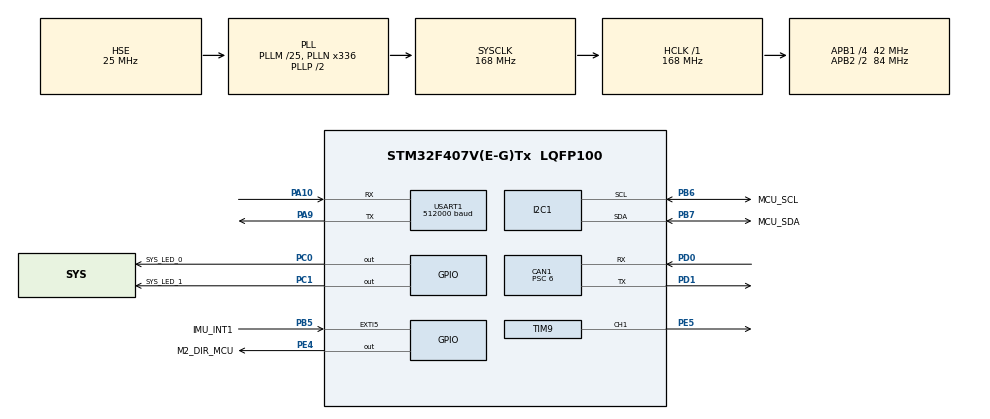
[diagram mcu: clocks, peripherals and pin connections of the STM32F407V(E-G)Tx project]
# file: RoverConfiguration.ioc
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CAN1.BS1=CAN_BS1_8TQ
CAN1.BS2=CAN_BS2_5TQ
CAN1.CalculateBaudRate=500000
CAN1.CalculateTimeBit=2000
CAN1.CalculateTimeQuantum=142.85714285714286
CAN1.Prescaler=6
CAN1.RFLM=ENABLE
CAN1.SJW=CAN_SJW_2TQ
CAN1.TXFP=ENABLE
Dma.Request0=USART1_RX
Dma.Request1=USART1_TX
Dma.USART1_RX.0.Direction=DMA_PERIPH_TO_MEMORY
Dma.USART1_RX.0.FIFOMode=DMA_FIFOMODE_DISABLE
Dma.USART1_RX.0.Instance=DMA2_Stream2
Dma.USART1_RX.0.MemDataAlignment=DMA_MDATAALIGN_BYTE
Dma.USART1_RX.0.MemInc=DMA_MINC_ENABLE
Dma.USART1_RX.0.Mode=DMA_NORMAL
Dma.USART1_RX.0.PeriphDataAlignment=DMA_PDATAALIGN_BYTE
Dma.USART1_RX.0.PeriphInc=DMA_PINC_DISABLE
Dma.USART1_RX.0.Priority=DMA_PRIORITY_HIGH
Dma.USART1_TX.1.Direction=DMA_MEMORY_TO_PERIPH
Dma.USART1_TX.1.FIFOMode=DMA_FIFOMODE_DISABLE
Dma.USART1_TX.1.Instance=DMA2_Stream7
Dma.USART1_TX.1.MemDataAlignment=DMA_MDATAALIGN_BYTE
Dma.USART1_TX.1.MemInc=DMA_MINC_ENABLE
Dma.USART1_TX.1.Mode=DMA_NORMAL
Dma.USART1_TX.1.PeriphDataAlignment=DMA_PDATAALIGN_BYTE
Dma.USART1_TX.1.PeriphInc=DMA_PINC_DISABLE
Dma.USART1_TX.1.Priority=DMA_PRIORITY_HIGH
FREERTOS.BinarySemaphores01=IMUBinarySem,Dynamic,NULL,Available
FREERTOS.MEMORY_ALLOCATION=2
FREERTOS.Tasks01=defaultTask,1,128,StartSysTask,As weak,NULL,Dynamic,NULL,NULL;myTask02,-3,512,StartPublisher2Task,As weak,NULL,Dynamic,NULL,NULL;myTask04,-3,128,StartServoTask,As weak,NULL,Dynamic,NULL,NULL;myTask05,-3,128,StartSysLEDTask,As weak,NULL,Dynamic,NULL,NULL;myTask06,-3,512,StartDriverTask,As weak,NULL,Dynamic,NULL,NULL;myTask07,-3,1024,StartIMUTask,As weak,NULL,Dynamic,NULL,NULL
FREERTOS.configMINIMAL_STACK_SIZE=128
Mcu.Family=STM32F4
Mcu.Name=STM32F407V(E-G)Tx
Mcu.Package=LQFP100
NVIC.CAN1_RX0_IRQn=true\:6\:0\:true\:false\:true\:true\:true\:true\:true
NVIC.CAN1_RX1_IRQn=true\:6\:0\:true\:false\:true\:true\:true\:true\:true
NVIC.CAN1_SCE_IRQn=true\:6\:0\:true\:false\:true\:true\:true\:true\:true
NVIC.CAN1_TX_IRQn=true\:6\:0\:true\:false\:true\:true\:true\:true\:true
NVIC.DMA2_Stream2_IRQn=true\:5\:0\:false\:false\:true\:true\:false\:true\:true
NVIC.DMA2_Stream7_IRQn=true\:5\:0\:false\:false\:true\:true\:false\:true\:true
NVIC.EXTI9_5_IRQn=true\:6\:0\:true\:false\:true\:true\:true\:true\:true
NVIC.PriorityGroup=NVIC_PRIORITYGROUP_4
NVIC.TIM1_UP_TIM10_IRQn=true\:15\:0\:false\:false\:true\:false\:false\:true\:true
NVIC.TIM8_TRG_COM_TIM14_IRQn=true\:5\:0\:false\:false\:true\:true\:true\:true\:true
NVIC.TimeBase=TIM1_UP_TIM10_IRQn
NVIC.TimeBaseIP=TIM1
NVIC.USART1_IRQn=true\:5\:0\:false\:false\:true\:true\:true\:true\:true
PA10.Mode=Asynchronous
PA10.Signal=USART1_RX
PA13.Mode=Serial_Wire
PA13.Signal=SYS_JTMS-SWDIO
PA14.Mode=Serial_Wire
PA14.Signal=SYS_JTCK-SWCLK
PA9.Mode=Asynchronous
PA9.Signal=USART1_TX
PB5.GPIO_Label=IMU_INT1
PB5.Signal=GPXTI5
PB6.GPIO_Label=MCU_SCL
PB6.Mode=I2C
PB6.Signal=I2C1_SCL
PB7.GPIO_Label=MCU_SDA
PB7.Mode=I2C
PB7.Signal=I2C1_SDA
PC0.GPIO_Label=SYS_LED_0
PC0.Signal=GPIO_Output
PC1.GPIO_Label=SYS_LED_1
PC1.Signal=GPIO_Output
PD0.Mode=CAN_Activate
PD0.Signal=CAN1_RX
PD1.Mode=CAN_Activate
PD1.Signal=CAN1_TX
PE4.GPIO_Label=M2_DIR_MCU
PE4.Signal=GPIO_Output
PE5.Signal=S_TIM9_CH1
PH0-OSC_IN.Mode=HSE-External-Oscillator
PH0-OSC_IN.Signal=RCC_OSC_IN
PH1-OSC_OUT.Mode=HSE-External-Oscillator
PH1-OSC_OUT.Signal=RCC_OSC_OUT
ProjectManager.HeapSize=0x3000
ProjectManager.StackSize=0x2000
ProjectManager.TargetToolchain=CMake
RCC.48MHZClocksFreq_Value=84000000
RCC.AHBFreq_Value=168000000
RCC.APB1CLKDivider=RCC_HCLK_DIV4
RCC.APB1Freq_Value=42000000
RCC.APB1TimFreq_Value=84000000
RCC.APB2CLKDivider=RCC_HCLK_DIV2
RCC.APB2Freq_Value=84000000
RCC.APB2TimFreq_Value=168000000
RCC.CortexFreq_Value=168000000
RCC.HCLKFreq_Value=168000000
RCC.HSE_VALUE=25000000
RCC.HSI_VALUE=16000000
RCC.LSE_VALUE=32768
RCC.PLLM=25
RCC.PLLN=336
RCC.PLLSourceVirtual=RCC_PLLSOURCE_HSE
RCC.SYSCLKFreq_VALUE=168000000
RCC.SYSCLKSource=RCC_SYSCLKSOURCE_PLLCLK
RCC.VCOOutputFreq_Value=336000000
SH.S_TIM9_CH1.0=TIM9_CH1,PWM Generation1 CH1
TIM14.AutoReloadPreload=TIM_AUTORELOAD_PRELOAD_DISABLE
TIM14.Period=1000
TIM14.Prescaler=83
TIM9.AutoReloadPreload=TIM_AUTORELOAD_PRELOAD_ENABLE
TIM9.Channel-PWM\ Generation1\ CH1=TIM_CHANNEL_1
TIM9.OCPolarity_1=TIM_OCPOLARITY_HIGH
TIM9.Period=1000-1
TIM9.Prescaler=168-1
TIM9.Pulse-PWM\ Generation1\ CH1=500
USART1.BaudRate=512000
USART1.VirtualMode=VM_ASYNC
VP_FREERTOS_VS_CMSIS_V1.Mode=CMSIS_V1
VP_SYS_VS_tim1.Mode=TIM1
VP_TIM14_VS_ClockSourceINT.Mode=Enable_Timer
board=custom

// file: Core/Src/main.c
/* USER CODE BEGIN Header */
/**
  ******************************************************************************
  * @file           : main.c
  * @brief          : Main program body
  ******************************************************************************
  * @attention
  *
  * Copyright (c) 2024 STMicroelectronics.
  * All rights reserved.
  *
  * This software is licensed under terms that can be found in the LICENSE file
  * in the root directory of this software component.
  * If no LICENSE file comes with this software, it is provided AS-IS.
  *
  ******************************************************************************
  */
/* USER CODE END Header */
#include "main.h"
#include "cmsis_os.h"
#include "can.h"
#include "dma.h"
#include "i2c.h"
#include "tim.h"
#include "usart.h"
#include "gpio.h"

/* USER CODE BEGIN Includes */
#include "maincpp.h"
/* USER CODE END Includes */

void SystemClock_Config(void);
void MX_FREERTOS_Init(void);

int main(void)
{

  /* MCU Configuration--------------------------------------------------------*/

  /* Reset of all peripherals, Initializes the Flash interface and the Systick. */
  HAL_Init();

  /* Configure the system clock */
  SystemClock_Config();

  /* Initialize all configured peripherals */
  MX_GPIO_Init();
  MX_DMA_Init();
  MX_CAN1_Init();
  MX_TIM14_Init();
  MX_USART1_UART_Init();
  MX_TIM9_Init();
  MX_I2C1_Init();

  /* Call init function for freertos objects (in cmsis_os2.c) */
  MX_FREERTOS_Init();

  /* Start scheduler */
  osKernelStart();

  /* We should never get here as control is now taken by the scheduler */

  /* Infinite loop */
  while (1)
  {

  }
}

void SystemClock_Config(void)
{
  RCC_OscInitTypeDef RCC_OscInitStruct = {0};
  RCC_ClkInitTypeDef RCC_ClkInitStruct = {0};

  /** Configure the main internal regulator output voltage
  */
  __HAL_RCC_PWR_CLK_ENABLE();
  __HAL_PWR_VOLTAGESCALING_CONFIG(PWR_REGULATOR_VOLTAGE_SCALE1);

  /** Initializes the RCC Oscillators according to the specified parameters
  * in the RCC_OscInitTypeDef structure.
  */
  RCC_OscInitStruct.OscillatorType = RCC_OSCILLATORTYPE_HSE;
  RCC_OscInitStruct.HSEState = RCC_HSE_ON;
  RCC_OscInitStruct.PLL.PLLState = RCC_PLL_ON;
  RCC_OscInitStruct.PLL.PLLSource = RCC_PLLSOURCE_HSE;
  RCC_OscInitStruct.PLL.PLLM = 25;
  RCC_OscInitStruct.PLL.PLLN = 336;
  RCC_OscInitStruct.PLL.PLLP = RCC_PLLP_DIV2;
  RCC_OscInitStruct.PLL.PLLQ = 4;
  if (HAL_RCC_OscConfig(&RCC_OscInitStruct) != HAL_OK)
  {
    Error_Handler();
  }

  /** Initializes the CPU, AHB and APB buses clocks
  */
  RCC_ClkInitStruct.ClockType = RCC_CLOCKTYPE_HCLK|RCC_CLOCKTYPE_SYSCLK
                              |RCC_CLOCKTYPE_PCLK1|RCC_CLOCKTYPE_PCLK2;
  RCC_ClkInitStruct.SYSCLKSource = RCC_SYSCLKSOURCE_PLLCLK;
  RCC_ClkInitStruct.AHBCLKDivider = RCC_SYSCLK_DIV1;
  RCC_ClkInitStruct.APB1CLKDivider = RCC_HCLK_DIV4;
  RCC_ClkInitStruct.APB2CLKDivider = RCC_HCLK_DIV2;

  if (HAL_RCC_ClockConfig(&RCC_ClkInitStruct, FLASH_LATENCY_5) != HAL_OK)
  {
    Error_Handler();
  }
}

void HAL_TIM_PeriodElapsedCallback(TIM_HandleTypeDef *htim)
{
  if (htim->Instance == TIM1) {
    HAL_IncTick();
  }
  /* USER CODE BEGIN Callback 1 */
	if (htim == canopenNodeSTM32->timerHandle) {
      canopen_app_interrupt();
  }
  /* USER CODE END Callback 1 */
}

void Error_Handler(void)
{
  __disable_irq();
  while (1)
  {
  }
}

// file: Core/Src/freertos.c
/* USER CODE BEGIN Header */
/**
  ******************************************************************************
  * File Name          : freertos.c
  * Description        : Code for freertos applications
  ******************************************************************************
  * @attention
  *
  * Copyright (c) 2024 STMicroelectronics.
  * All rights reserved.
  *
  * This software is licensed under terms that can be found in the LICENSE file
  * in the root directory of this software component.
  * If no LICENSE file comes with this software, it is provided AS-IS.
  *
  ******************************************************************************
  */
/* USER CODE END Header */

#include "FreeRTOS.h"
#include "task.h"
#include "main.h"
#include "cmsis_os.h"

osThreadId defaultTaskHandle;
osThreadId myTask02Handle;
osThreadId myTask04Handle;
osThreadId myTask05Handle;
osThreadId myTask06Handle;
osThreadId myTask07Handle;
osSemaphoreId IMUBinarySemHandle;

void StartSysTask(void const * argument);
void StartPublisher2Task(void const * argument);
void StartServoTask(void const * argument);
void StartSysLEDTask(void const * argument);
void StartDriverTask(void const * argument);
void StartIMUTask(void const * argument);

void MX_FREERTOS_Init(void); /* (MISRA C 2004 rule 8.1) */

/* GetIdleTaskMemory prototype (linked to static allocation support) */
void vApplicationGetIdleTaskMemory( StaticTask_t **ppxIdleTaskTCBBuffer, StackType_t **ppxIdleTaskStackBuffer, uint32_t *pulIdleTaskStackSize );

/* USER CODE BEGIN GET_IDLE_TASK_MEMORY */
static StaticTask_t xIdleTaskTCBBuffer;
static StackType_t xIdleStack[configMINIMAL_STACK_SIZE];

void vApplicationGetIdleTaskMemory( StaticTask_t **ppxIdleTaskTCBBuffer, StackType_t **ppxIdleTaskStackBuffer, uint32_t *pulIdleTaskStackSize )
{
  *ppxIdleTaskTCBBuffer = &xIdleTaskTCBBuffer;
  *ppxIdleTaskStackBuffer = &xIdleStack[0];
  *pulIdleTaskStackSize = configMINIMAL_STACK_SIZE;
  /* place for user code */
}
/* USER CODE END GET_IDLE_TASK_MEMORY */

void MX_FREERTOS_Init(void) {

  /* Create the semaphores(s) */
  /* definition and creation of IMUBinarySem */
  osSemaphoreDef(IMUBinarySem);
  IMUBinarySemHandle = osSemaphoreCreate(osSemaphore(IMUBinarySem), 1);

  /* Create the thread(s) */
  /* definition and creation of defaultTask */
  osThreadDef(defaultTask, StartSysTask, osPriorityAboveNormal, 0, 128);
  defaultTaskHandle = osThreadCreate(osThread(defaultTask), NULL);

  /* definition and creation of myTask02 */
  osThreadDef(myTask02, StartPublisher2Task, osPriorityIdle, 0, 512);
  myTask02Handle = osThreadCreate(osThread(myTask02), NULL);

  /* definition and creation of myTask04 */
  osThreadDef(myTask04, StartServoTask, osPriorityIdle, 0, 128);
  myTask04Handle = osThreadCreate(osThread(myTask04), NULL);

  /* definition and creation of myTask05 */
  osThreadDef(myTask05, StartSysLEDTask, osPriorityIdle, 0, 128);
  myTask05Handle = osThreadCreate(osThread(myTask05), NULL);

  /* definition and creation of myTask06 */
  osThreadDef(myTask06, StartDriverTask, osPriorityIdle, 0, 512);
  myTask06Handle = osThreadCreate(osThread(myTask06), NULL);

  /* definition and creation of myTask07 */
  osThreadDef(myTask07, StartIMUTask, osPriorityIdle, 0, 1024);
  myTask07Handle = osThreadCreate(osThread(myTask07), NULL);

}

__weak void StartSysTask(void const * argument)
{
  for(;;)
  {
    osDelay(1);
  }
}

__weak void StartPublisher2Task(void const * argument)
{
  for(;;)
  {
    osDelay(1);
  }
}

__weak void StartServoTask(void const * argument)
{
  for(;;)
  {
    osDelay(1);
  }
}

__weak void StartSysLEDTask(void const * argument)
{
  for(;;)
  {
    osDelay(1);
  }
}

__weak void StartDriverTask(void const * argument)
{
  for(;;)
  {
    osDelay(1);
  }
}

__weak void StartIMUTask(void const * argument)
{
  for(;;)
  {
    osDelay(1);
  }
}
